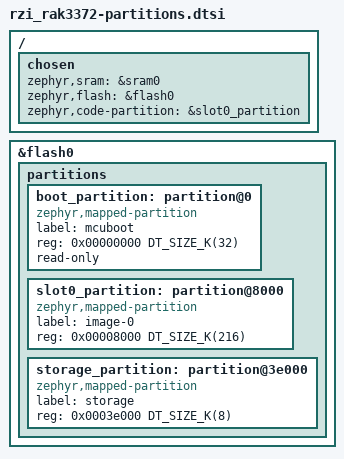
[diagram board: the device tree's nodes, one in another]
/* SPDX-License-Identifier: Apache-2.0 */
/*
 * rzi_rak3372 flash map (STM32WLE5, 256 KiB).
 *
 * Single slot: 256 KB cannot hold two signed images plus storage. There is
 * no image-1, so LoRaWAN FUOTA is not supported. Flash the merged
 * image (mcuboot + signed slot0).
 */

/ {
	chosen {
		zephyr,sram = &sram0;
		zephyr,flash = &flash0;
		zephyr,code-partition = &slot0_partition;
	};
};

&flash0 {
	partitions {
		ranges;
		#address-cells = <1>;
		#size-cells = <1>;

		boot_partition: partition@0 {
			compatible = "zephyr,mapped-partition";
			label = "mcuboot";
			reg = <0x00000000 DT_SIZE_K(32)>;
			read-only;
		};

		slot0_partition: partition@8000 {
			compatible = "zephyr,mapped-partition";
			label = "image-0";
			reg = <0x00008000 DT_SIZE_K(216)>;
		};

		storage_partition: partition@3e000 {
			compatible = "zephyr,mapped-partition";
			label = "storage";
			reg = <0x0003e000 DT_SIZE_K(8)>;
		};
	};
};
